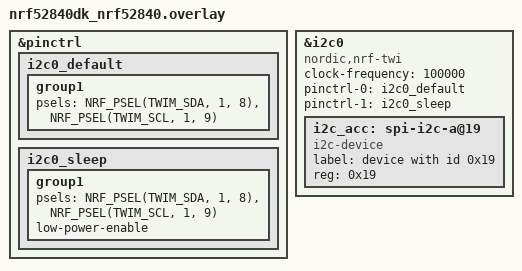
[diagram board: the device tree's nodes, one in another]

&pinctrl {
    i2c0_default: i2c0_default {
		group1 {
			psels = <NRF_PSEL(TWIM_SDA, 1, 8)>,
				<NRF_PSEL(TWIM_SCL, 1, 9)>;
		};
	};

	i2c0_sleep: i2c0_sleep {
		group1 {
			psels = <NRF_PSEL(TWIM_SDA, 1, 8)>,
				<NRF_PSEL(TWIM_SCL, 1, 9)>;
			low-power-enable;
		};
	};
};

&i2c0 {										
	compatible = "nordic,nrf-twi";			
	status = "okay";						
	clock-frequency = <100000>;				
	pinctrl-0 = <&i2c0_default>;
	pinctrl-1 = <&i2c0_sleep>;
	pinctrl-names = "default", "sleep";

	i2c_acc: spi-i2c-a@19 {		
		compatible = "i2c-device";		
		label = "device with id 0x19";	
		reg = <0x19>;						
	};

	// i2c_mag: spi-i2c-a@1e {		
	// 	compatible = "i2c-device";		
	// 	label = "device with id 0x1E";	
	// 	reg = <0x1E>;						
	// };
};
